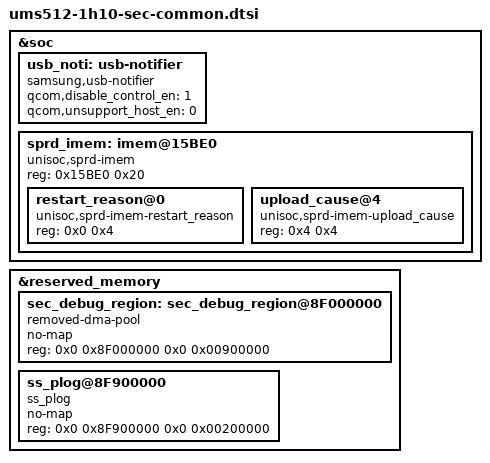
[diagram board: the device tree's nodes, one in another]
/* Copyright (c) 2019, The Linux Foundation. All rights reserved.
 *
 * This program is free software; you can redistribute it and/or modify
 * it under the terms of the GNU General Public License version 2 and
 * only version 2 as published by the Free Software Foundation.
 *
 * This program is distributed in the hope that it will be useful,
 * but WITHOUT ANY WARRANTY; without even the implied warranty of
 * MERCHANTABILITY or FITNESS FOR A PARTICULAR PURPOSE.  See the
 * GNU General Public License for more details.
 */

&soc {
	usb_noti: usb-notifier {
		compatible = "samsung,usb-notifier";
		qcom,disable_control_en = <1>;
		qcom,unsupport_host_en = <0>;
	};

	sprd_imem: imem@15BE0 {
		compatible = "unisoc,sprd-imem";
		reg = <0x15BE0 0x20>;
		ranges = <0x0 0x0 0x15BE0 0x20>;
		#address-cells = <1>;
		#size-cells = <1>;
		
		restart_reason@0 {
			compatible = "unisoc,sprd-imem-restart_reason";
			reg = <0x0 0x4>;
		};

		upload_cause@4 {
			compatible = "unisoc,sprd-imem-upload_cause";
			reg = <0x4 0x4>;
		};
	};
};

&reserved_memory {
	/* CONFIG_SEC_DEBUG reserves 9MB */
	sec_debug_region: sec_debug_region@8F000000 {
		compatible = "removed-dma-pool";
		no-map;
		reg = <0x0 0x8F000000 0x0 0x00900000>;
	};

	ss_plog@8F900000 {
		compatible = "ss_plog";
		no-map;
		reg = <0x0 0x8F900000 0x0 0x00200000>;
	};
};
